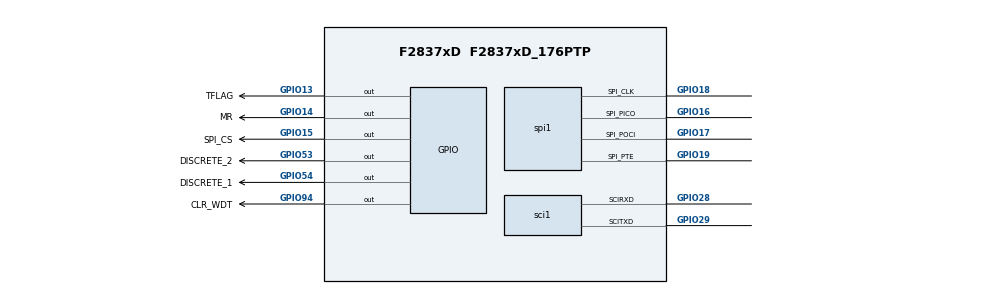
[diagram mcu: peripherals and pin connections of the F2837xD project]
/**
 * @cliArgs --device "F2837xD" --package "F2837xD_176PTP" --part "F2837xD_176PTP" --context "CPU1" --product "C2000WARE@5.01.00.00"
 * @versions {"tool":"1.16.2+3028"}
 */

/**
 * Import the modules used in this configuration.
 */
const cputimer  = scripting.addModule("/driverlib/cputimer.js", {}, false);
const cputimer1 = cputimer.addInstance();
const gpio      = scripting.addModule("/driverlib/gpio.js", {}, false);
const gpio1     = gpio.addInstance();
const gpio2     = gpio.addInstance();
const gpio3     = gpio.addInstance();
const gpio4     = gpio.addInstance();
const gpio5     = gpio.addInstance();
const gpio6     = gpio.addInstance();
const sci       = scripting.addModule("/driverlib/sci.js", {}, false);
const sci1      = sci.addInstance();
const spi       = scripting.addModule("/driverlib/spi.js", {}, false);
const spi1      = spi.addInstance();

/**
 * Write custom configuration values to the imported modules.
 */
cputimer1.$name                     = "myCPUTIMER0";
cputimer1.timerPrescaler            = 1;
cputimer1.enableInterrupt           = true;
cputimer1.startTimer                = true;
cputimer1.registerInterrupts        = true;
cputimer1.timerPeriod               = 5000000;
cputimer1.timerInt.interruptHandler = "cpuTimer0ISR";
cputimer1.timerInt.enableInterrupt  = true;

gpio1.$name           = "MR";
gpio1.direction       = "GPIO_DIR_MODE_OUT";
gpio1.gpioPin.$assign = "GPIO14";

gpio2.$name           = "TFLAG";
gpio2.qualMode        = "GPIO_QUAL_6SAMPLE";
gpio2.padConfig       = "PULLUP";
gpio2.gpioPin.$assign = "GPIO13";

gpio3.$name             = "SPI_CS";
gpio3.direction         = "GPIO_DIR_MODE_OUT";
gpio3.writeInitialValue = true;
gpio3.initialValue      = 1;
gpio3.gpioPin.$assign   = "GPIO15";

gpio4.qualMode        = "GPIO_QUAL_6SAMPLE";
gpio4.$name           = "DISCRETE_1";
gpio4.gpioPin.$assign = "GPIO54";

gpio5.$name             = "CLR_WDT";
gpio5.direction         = "GPIO_DIR_MODE_OUT";
gpio5.writeInitialValue = true;
gpio5.initialValue      = 1;
gpio5.gpioPin.$assign   = "GPIO94";

gpio6.qualMode        = "GPIO_QUAL_6SAMPLE";
gpio6.$name           = "DISCRETE_2";
gpio6.gpioPin.$assign = "GPIO53";

sci1.$name                    = "mySCI0";
sci1.registerInterrupts       = true;
sci1.rxFifo                   = "SCI_FIFO_RX1";
sci1.enabledFIFOInterrupts    = ["SCI_INT_RXFF"];
sci1.baudRates                = 9600;
sci1.sci.$assign              = "SCIA";
sci1.sci.scirxdPin.$assign    = "GPIO28";
sci1.sci.scitxdPin.$assign    = "GPIO29";
sci1.sciRXInt.enableInterrupt = true;

spi1.$name                   = "mySPI0";
spi1.mode                    = "SPI_MODE_CONTROLLER";
spi1.useInterrupts           = false;
spi1.useFifo                 = false;
spi1.emulationMode           = "SPI_EMULATION_FREE_RUN";
spi1.dataWidth               = "8";
spi1.transferProtocol        = "SPI_PROT_POL1PHA0";
spi1.spi.$assign             = "SPIA";
spi1.spi.spi_picoPin.$assign = "GPIO16";
spi1.spi.spi_pociPin.$assign = "GPIO17";
spi1.spi.spi_clkPin.$assign  = "GPIO18";
spi1.spi.spi_ptePin.$assign  = "GPIO19";
